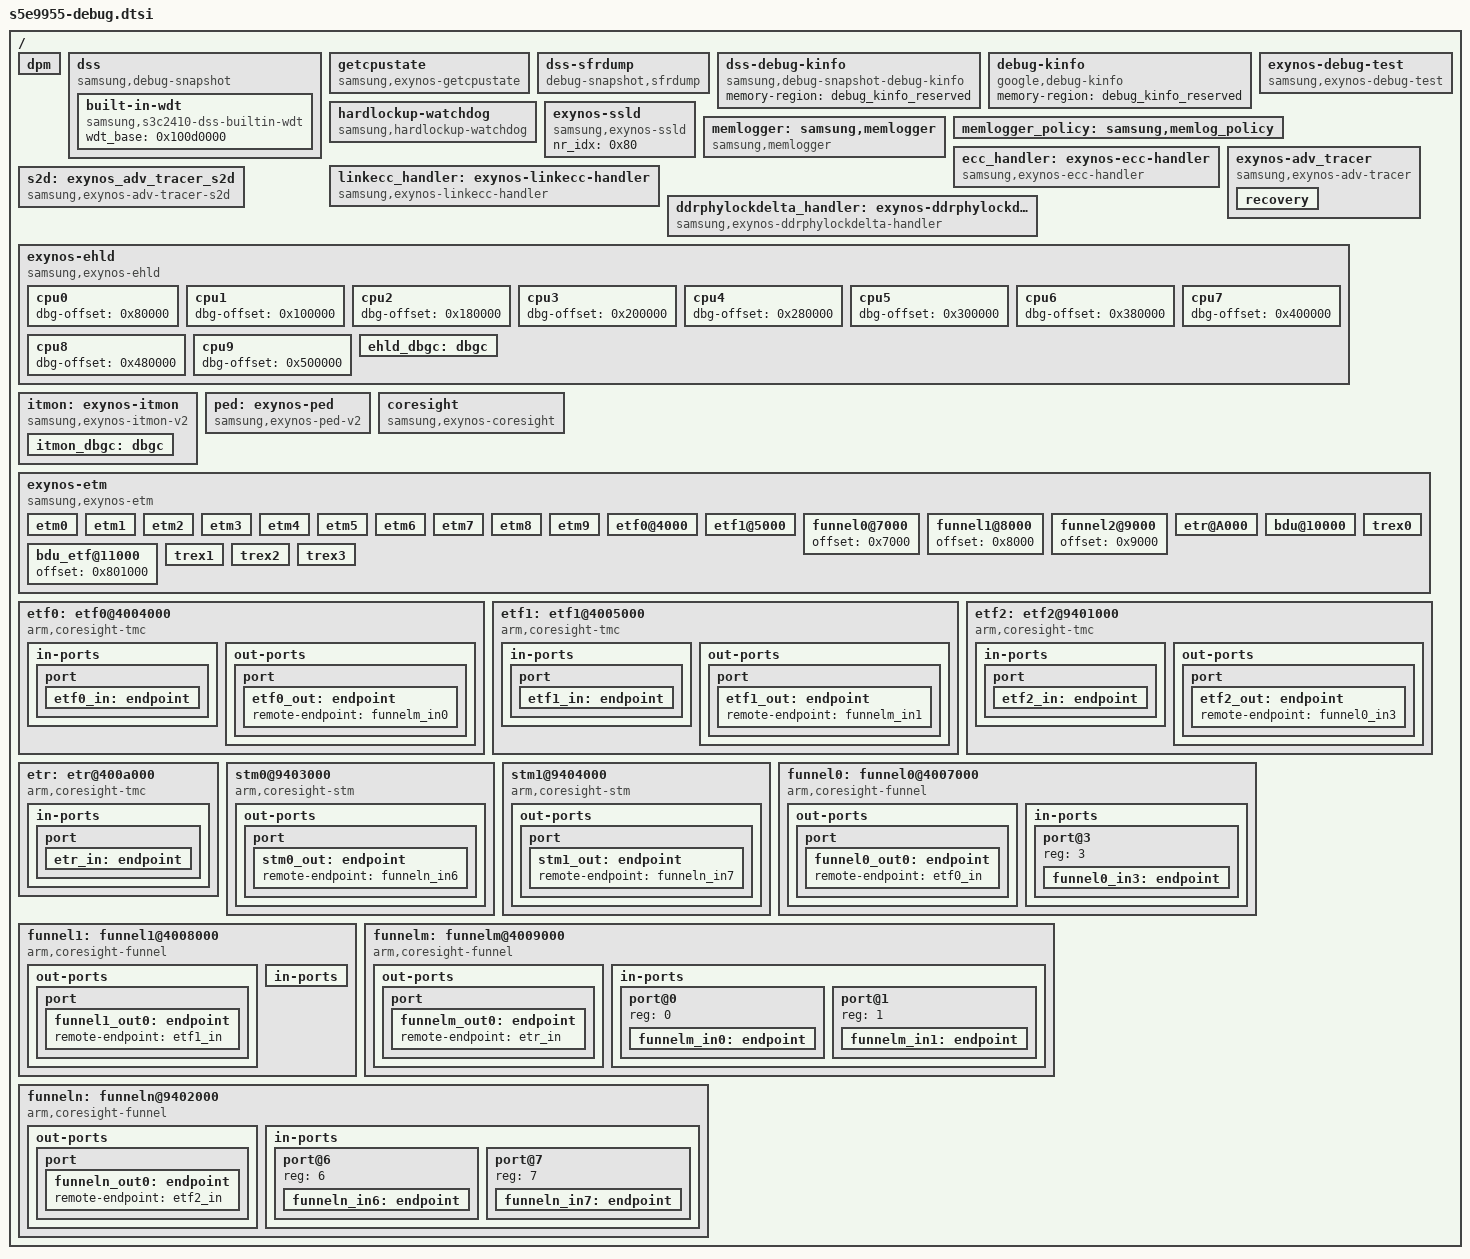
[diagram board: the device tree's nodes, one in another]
// SPDX-License-Identifier: GPL-2.0-only

#include <dt-bindings/interrupt-controller/s5e9955.h>
#include <dt-bindings/input/linux-event-codes.h>

/ {
	dpm: dpm {
	};

	dss: dss {
		compatible = "samsung,debug-snapshot";
		reg = <0 0x16915300 0xe00>;
		enable_cpuidle_dbg;
		panic_to_wdt = <0>;
		last_kmsg = <1>;
		hold-key = <KEY_VOLUMEDOWN>;
		trigger-key = <KEY_POWER>;
		scratch-disable = <0>;
		scratch-offset = <0x190>; /* SYSIP_DAT0 */
		scratch-bit = <6>;
		console_kmsg = <0>;
		freq_names = "CPUCL0", "CPUCL1", "CPUCL2", "CPUCL3", "DSU",
				"G3D", "MIF", "INT", "NPU", "AUD", "INTCAM",
				"CAM", "DISP", "CSIS", "ISP", "MFC", "MFD",
				"ICPU", "DSP", "DNC", "HSI0", "UFD", "UNPU";
		memory-region = <&header>, <&log_kernel>, <&log_s2d>,
				<&log_first>, <&log_arrdumprst>, <&log_platform>,
				<&log_kevents>, <&log_backtrace>, <&log_kevents_small>,
				<&wdtmsg>;
		built-in-wdt {
			compatible = "samsung,s3c2410-dss-builtin-wdt";
			wdt_base = <0x100d0000>;
		};
	};

	getcpustate {
		compatible = "samsung,exynos-getcpustate";
		reg = <0x0 0x2fc70000 0x2000>;
		reg-names = "dsu_base";
		control_by_dsu;
		core_ppuhwstat_offset = <0x1538>, <0x1538>, <0x1540>, <0x1540>,
					<0x1544>, <0x1544>, <0x1548>, <0x1548>,
					<0x154c>, <0x154c>;
		core_ppuhwstat_lsb = <0>, <16>, <0>, <16>,
				     <0>, <16>, <0>, <16>,
				     <0>, <16>;
	};

	dss-sfrdump {
		compatible = "debug-snapshot,sfrdump";
		/* -----------<< Example >>-------------------
		dump-info {
			#address-cells = <1>;
			#size-cells = <1>;

			gic-setenable {
				reg = <0x11f01100 0x100>;
			};
			gic-setpend {
				reg = <0x11f01200 0x100>;
			};
			gic-setactive {
				reg = <0x11f01300 0x100>;
			};
		};
		*/
	};

	dss-debug-kinfo {
		compatible = "samsung,debug-snapshot-debug-kinfo";
		memory-region = <&debug_kinfo_reserved>;
	};

	debug-kinfo {
		compatible = "google,debug-kinfo";
		memory-region = <&debug_kinfo_reserved>;
	};

	hardlockup-watchdog {
		compatible = "samsung,hardlockup-watchdog";
	};

	exynos-debug-test {
		compatible = "samsung,exynos-debug-test";
		ps_hold_control_offset = <0x3F90>;
		scratch-offset = <0x0190>; /* SYSIP_DAT0 */
		dram-init-bit = <0x4>;
		nr_cpu = <0x10>;
		nr_little_cpu = <0x2>;
		nr_mid_cpu = <0x5>;
		nr_mid_hf_cpu = <0x2>;
		nr_big_cpu = <0x1>;
		little_cpu_start = <0x0>;
		mid_cpu_start = <0x2>;
		mid_hf_cpu_start = <0x7>;
		big_cpu_start = <0x9>;
	};

	exynos-ssld {
		compatible = "samsung,exynos-ssld";
		nr_idx = <0x80>;
	};

	memlogger: samsung,memlogger {
		compatible = "samsung,memlogger";
		memory-region = <&memlog_mem>;
		samsung,bl-node = <&memlog_bl_base>;
	};

	memlogger_policy: samsung,memlog_policy {
		samsung,log-level = <4>;
		samsung,file-default-status = <1>;
		samsung,mem-constraint = <0>;
		samsung,mem-to-file-allow = <1>;
	};

	ecc_handler: exynos-ecc-handler {
		compatible = "samsung,exynos-ecc-handler";
		interrupts = <GIC_SPI INTREQ__CPUCL0_CLUSTERERRIRQ IRQ_TYPE_LEVEL_HIGH>,
			<GIC_SPI INTREQ__CPUCL0_COMPLEXERRIRQ_0 IRQ_TYPE_LEVEL_HIGH>,
			<GIC_SPI INTREQ__CPUCL0_COREERRIRQ_0 IRQ_TYPE_LEVEL_HIGH>,
			<GIC_SPI INTREQ__CPUCL0_COREERRIRQ_1 IRQ_TYPE_LEVEL_HIGH>,
			<GIC_SPI INTREQ__CPUCL0_COREERRIRQ_2 IRQ_TYPE_LEVEL_HIGH>,
			<GIC_SPI INTREQ__CPUCL0_COREERRIRQ_3 IRQ_TYPE_LEVEL_HIGH>,
			<GIC_SPI INTREQ__CPUCL0_COREERRIRQ_4 IRQ_TYPE_LEVEL_HIGH>,
			<GIC_SPI INTREQ__CPUCL0_COREERRIRQ_5 IRQ_TYPE_LEVEL_HIGH>,
			<GIC_SPI INTREQ__CPUCL0_COREERRIRQ_6 IRQ_TYPE_LEVEL_HIGH>,
			<GIC_SPI INTREQ__CPUCL0_COREERRIRQ_7 IRQ_TYPE_LEVEL_HIGH>,
			<GIC_SPI INTREQ__CPUCL0_COREERRIRQ_8 IRQ_TYPE_LEVEL_HIGH>,
			<GIC_SPI INTREQ__CPUCL0_COREERRIRQ_9 IRQ_TYPE_LEVEL_HIGH>,
			<GIC_SPI INTREQ__CPUCL0_CLUSTERFAULTIRQ IRQ_TYPE_LEVEL_HIGH>,
			<GIC_SPI INTREQ__CPUCL0_COMPLEXFAULTIRQ_0 IRQ_TYPE_LEVEL_HIGH>,
			<GIC_SPI INTREQ__CPUCL0_COREFAULTIRQ_0 IRQ_TYPE_LEVEL_HIGH>,
			<GIC_SPI INTREQ__CPUCL0_COREFAULTIRQ_1 IRQ_TYPE_LEVEL_HIGH>,
			<GIC_SPI INTREQ__CPUCL0_COREFAULTIRQ_2 IRQ_TYPE_LEVEL_HIGH>,
			<GIC_SPI INTREQ__CPUCL0_COREFAULTIRQ_3 IRQ_TYPE_LEVEL_HIGH>,
			<GIC_SPI INTREQ__CPUCL0_COREFAULTIRQ_4 IRQ_TYPE_LEVEL_HIGH>,
			<GIC_SPI INTREQ__CPUCL0_COREFAULTIRQ_5 IRQ_TYPE_LEVEL_HIGH>,
			<GIC_SPI INTREQ__CPUCL0_COREFAULTIRQ_6 IRQ_TYPE_LEVEL_HIGH>,
			<GIC_SPI INTREQ__CPUCL0_COREFAULTIRQ_7 IRQ_TYPE_LEVEL_HIGH>,
			<GIC_SPI INTREQ__CPUCL0_COREFAULTIRQ_8 IRQ_TYPE_LEVEL_HIGH>,
			<GIC_SPI INTREQ__CPUCL0_COREFAULTIRQ_9 IRQ_TYPE_LEVEL_HIGH>,
			<GIC_SPI INTREQ__CPUCL0_CLUSTERCRITIRQ IRQ_TYPE_LEVEL_HIGH>;
		interrupt-names = "Uncorrectable errors on the L3 data, tag or snoop filter RAMs",
			"Core0-1 Complex, Uncorrectable errors on the L2 data or tag RAMs",
			"Core0, Uncorrectable errors on the L1 data or tag RAMs",
			"Core1, Uncorrectable errors on the L1 data or tag RAMs",
			"Core2, Uncorrectable errors on the L1 data, tag or L2 data, tag RAMs",
			"Core3, Uncorrectable errors on the L1 data, tag or L2 data, tag RAMs",
			"Core4, Uncorrectable errors on the L1 data, tag or L2 data, tag RAMs",
			"Core5, Uncorrectable errors on the L1 data, tag or L2 data, tag RAMs",
			"Core6, Uncorrectable errors on the L1 data, tag or L2 data, tag RAMs",
			"Core7, Uncorrectable errors on the L1 data, tag or L2 data, tag RAMs",
			"Core8, Uncorrectable errors on the L1 data, tag or L2 data, tag RAMs",
			"Core9, Uncorrectable errors on the L1 data, tag or L2 data, tag RAMs",
			"FAULTIRQ(Single errors or Deffered errors) on the L3 data, tag or snoop filter RAMs",
			"Core0-1 Complex, FAULTIRQ(Single bit flip 100 times) on the L2 data or tag RAMs",
			"Core0, FAULTIRQ(Single bit flip 100 times) on the L1 data or tag RAMs",
			"Core1, FAULTIRQ(Single bit flip 100 times) on the L1 data or tag RAMs",
			"Core2, FAULTIRQ(Single bit flip 100 times) on the L1 data, tag or L2 data, tag RAMs",
			"Core3, FAULTIRQ(Single bit flip 100 times) on the L1 data, tag or L2 data, tag RAMs",
			"Core4, FAULTIRQ(Single bit flip 100 times) on the L1 data, tag or L2 data, tag RAMs",
			"Core5, FAULTIRQ(Single bit flip 100 times) on the L1 data, tag or L2 data, tag RAMs",
			"Core6, FAULTIRQ(Single bit flip 100 times) on the L1 data, tag or L2 data, tag RAMs",
			"Core7, FAULTIRQ(Single bit flip 100 times) on the L1 data, tag or L2 data, tag RAMs",
			"Core8, FAULTIRQ(Single bit flip 100 times) on the L1 data, tag or L2 data, tag RAMs",
			"Core9, FAULTIRQ(Single bit flip 100 times) on the L1 data, tag or L2 data, tag RAMs",
			"CRITIRQ(more than 2-bit bit-flip) on snoop filter";
		interrupt-affinity = <0x3ff>, <0x3>,
				<0x1>, <0x2>,
				<0x4>, <0x8>, <0x10>, <0x20>, <0x40>,
				<0x80>, <0x100>, <0x200>,
				<0x3ff>, <0x3>,
				<0x1>, <0x2>,
				<0x4>, <0x8>, <0x10>, <0x20>, <0x40>,
				<0x80>, <0x100>, <0x200>,
				<0x3ff>;
		policy = <0x0>, <0x0>,
				<0x0>, <0x0>,
				<0x0>, <0x0>, <0x0>, <0x0>, <0x0>,
				<0x0>, <0x0>, <0x0>,
				<0x1>, <0x0>,
				<0x0>, <0x0>,
				<0x0>, <0x0>, <0x0>, <0x0>, <0x0>,
				<0x0>, <0x0>, <0x0>,
				<0x0>;
	};
	
	linkecc_handler: exynos-linkecc-handler {
		compatible = "samsung,exynos-linkecc-handler";
		interrupts = <GIC_SPI INTREQ__DMC_ECC_CORERR_MIF0 IRQ_TYPE_LEVEL_HIGH>,
			<GIC_SPI INTREQ__DMC_ECC_UNCORERR_MIF0 IRQ_TYPE_LEVEL_HIGH>,
			<GIC_SPI INTREQ__DMC_ECC_CORERR_MIF1 IRQ_TYPE_LEVEL_HIGH>,
			<GIC_SPI INTREQ__DMC_ECC_UNCORERR_MIF1 IRQ_TYPE_LEVEL_HIGH>,
			<GIC_SPI INTREQ__DMC_ECC_CORERR_MIF2 IRQ_TYPE_LEVEL_HIGH>,
			<GIC_SPI INTREQ__DMC_ECC_UNCORERR_MIF2 IRQ_TYPE_LEVEL_HIGH>,
			<GIC_SPI INTREQ__DMC_ECC_CORERR_MIF3 IRQ_TYPE_LEVEL_HIGH>,
			<GIC_SPI INTREQ__DMC_ECC_UNCORERR_MIF3 IRQ_TYPE_LEVEL_HIGH>;
		interrupt-names = "Correctable error on CH0",
			"Uncorrectable errors on CH0",
			"Correctable error on CH1",
			"Uncorrectable errors on CH1",
			"Correctable error on CH2",
			"Uncorrectable errors on CH2",
			"Correctable error on CH3",
			"Uncorrectable errors on CH3";
		channel = <0x0>,<0x0>,<0x1>,<0x1>,<0x2>,<0x2>,<0x3>,<0x3>;
		clr_offs = <0x604>,<0x704>,<0x604>,<0x704>,<0x604>,<0x704>,<0x604>,<0x704>;
		base = <0x2D03F000>,<0x2D23F000>,<0x2D43F000>,<0x2D63F000>;
		debug_info = <0x02086400>;
	};	

	ddrphylockdelta_handler: exynos-ddrphylockdelta-handler {
		compatible = "samsung,exynos-ddrphylockdelta-handler";
		interrupts = <GIC_SPI INTREQ__DDRPHY_LOCKDELTA_MIF0 IRQ_TYPE_LEVEL_HIGH>,
			<GIC_SPI INTREQ__DDRPHY_LOCKDELTA_MIF1 IRQ_TYPE_LEVEL_HIGH>,
			<GIC_SPI INTREQ__DDRPHY_LOCKDELTA_MIF2 IRQ_TYPE_LEVEL_HIGH>,
			<GIC_SPI INTREQ__DDRPHY_LOCKDELTA_MIF3 IRQ_TYPE_LEVEL_HIGH>;
		interrupt-names = "DDRPHY Lockvalue Delta error on CH0",
			"DDRPHY Lockvalue Delta error on CH1",
			"DDRPHY Lockvalue Delta error on CH2",
			"DDRPHY Lockvalue Delta error on CH3";
		ch = <0x0>,<0x1>,<0x2>,<0x3>;
		base = <0x2D040000>,<0x2D240000>,<0x2D440000>,<0x2D640000>;
	};
	
	exynos-adv_tracer {
		compatible = "samsung,exynos-adv-tracer";
		reg = <0x0 0x13c10000 0x1000>;
		reg-names = "mailbox";
		interrupts = <GIC_SPI INTREQ__MAILBOX_DBGCORE2AP IRQ_TYPE_LEVEL_HIGH>;
		status = "ok";
		recovery {
			chip_name = "s5e9955";
			pmlink_out = <0x3e00>;
			pmlink_request = <0x25a0>;
			rst_seq = <0x0018>;
		};
	};

	s2d: exynos_adv_tracer_s2d {
		compatible = "samsung,exynos-adv-tracer-s2d";
		plugin-len = <3>;
		plugin-name = "S2D";
		pmu-burnin-ctrl = <0x3d48>;
		sel-scanmode-bit = <25>;
		dbgsel-sw-bit = <4>;
		pmu-rst-seq = <0x0018>;
		pmu-rst-seq-safe-mode-bit = <31>;
		status = "ok";
	};

	exynos-ehld {
		compatible = "samsung,exynos-ehld";
		status = "okay";
		cpu-end = <0x1>, <0x5>, <0x8>, <0x9>;
		reg = <0 0x2FCD0000 0x1000>,
			<0 0x2FCE0000 0x1000>,
			<0 0x2FCF0000 0x1000>,
			<0 0x2FD00000 0x1000>,
			<0 0x2FC90000 0x1000>,
			<0 0x2FCA0000 0x1000>,
			<0 0x2FCB0000 0x1000>,
			<0 0x2FCC0000 0x1000>;
		cs_base = <0x5000000>;
		version = <3>;
		cpu0 {
			dbg-offset = <0x80000>;
		};
		cpu1 {
			dbg-offset = <0x100000>;
		};
		cpu2 {
			dbg-offset = <0x180000>;
		};
		cpu3 {
			dbg-offset = <0x200000>;
		};
		cpu4 {
			dbg-offset = <0x280000>;
		};
		cpu5 {
			dbg-offset = <0x300000>;
		};
		cpu6 {
			dbg-offset = <0x380000>;
		};
		cpu7 {
			dbg-offset = <0x400000>;
		};
		cpu8 {
			dbg-offset = <0x480000>;
		};
		cpu9 {
			dbg-offset = <0x500000>;
		};

		ehld_dbgc: dbgc {
			/* IPC */
			plugin-len = <4>;
			plugin-name = "ELD";
			support = <1>;
			interval = <100>;
			threshold = <0x5000000>;
			judge = <1>;
			support-clear-data;
		};
	};

	itmon: exynos-itmon {
		compatible = "samsung,exynos-itmon-v2";
		memory-region = <&log_itmon>, <&log_itmon_history>;
		interrupts = <GIC_SPI INTREQ__TREX_DEBUG IRQ_TYPE_LEVEL_HIGH>;
		interrupt-affinity = <0x3ff>;
		support-irq-oring;
		big-bus-supporting;
		status = "ok";
		itmon_dbgc: dbgc {
			/* IPC */
			plugin-len = <3>;
			plugin-name = "ITM";
		};
	};

	ped: exynos-ped {
		compatible = "samsung,exynos-ped-v2";
		interrupts = <GIC_SPI INTREQ__PARITY_LH IRQ_TYPE_LEVEL_HIGH>;
		status = "okay";
	};

	coresight {
		compatible = "samsung,exynos-coresight";
		dbg_base = <0x5090000>, <0x5110000>, <0x5190000>, <0x5210000>,
			   <0x5290000>, <0x5310000>, <0x5390000>, <0x5410000>,
			   <0x5490000>, <0x5510000>;
		cti_base = <0x50f0000>, <0x5170000>, <0x51f0000>, <0x5270000>,
			   <0x52f0000>, <0x5370000>, <0x53f0000>, <0x5470000>,
			   <0x54f0000>, <0x5570000>;
		pmu_base = <0x50a0000>, <0x5120000>, <0x51a0000>, <0x5220000>,
			   <0x52a0000>, <0x5320000>, <0x53a0000>, <0x5420000>,
			   <0x54a0000>, <0x5520000>;
		gpr_base = <0x4001000>;
		dbgack-mask = <0x1ff00000>;
		halt = <0>;
		retention = <0>;
	};

	exynos-etm {
		compatible = "samsung,exynos-etm";
		cs_base = <0x4000000>;
		boot-start = <0>;
		funnel-num = <3>;
		funnel-port-num = <8>;
		etf-num = <2>;
		trex-num = <4>;
		/* funnel-port = <(funnel num) (port num)>; */
		etm0 {
			device_type = "etm";
			offset = <0x10b0000>;
			funnel-port = <0 0>;
		};
		etm1 {
			device_type = "etm";
			offset = <0x1130000>;
			funnel-port = <0 0>;
		};
		etm2 {
			device_type = "etm";
			offset = <0x11b0000>;
			funnel-port = <0 0>;
		};
		etm3 {
			device_type = "etm";
			offset = <0x1230000>;
			funnel-port = <0 0>;
		};
		etm4 {
			device_type = "etm";
			offset = <0x12b0000>;
			funnel-port = <0 0>;
		};
		etm5 {
			device_type = "etm";
			offset = <0x1330000>;
			funnel-port = <0 0>;
		};
		etm6 {
			device_type = "etm";
			offset = <0x13b0000>;
			funnel-port = <0 0>;
		};
		etm7 {
			device_type = "etm";
			offset = <0x1430000>;
			funnel-port = <0 0>;
		};
		etm8 {
			device_type = "etm";
			offset = <0x14b0000>;
			funnel-port = <0 0>;
		};
		etm9 {
			device_type = "etm";
			offset = <0x1530000>;
			funnel-port = <0 0>;
		};
		etf0@4000 {
			device_type = "etf";
			offset = <0x4000>;
			funnel-port = <2 0>;
		};
		etf1@5000 {
			device_type = "etf";
			offset = <0x5000>;
			funnel-port = <2 1>;
		};
		funnel0@7000 {
			device_type = "funnel";
			offset = <0x7000>;
		};
		funnel1@8000 {
			device_type = "funnel";
			offset = <0x8000>;
		};
		funnel2@9000 {
			device_type = "funnel";
			offset = <0x9000>;
		};
		etr@A000 {
			device_type = "etr";
			sfr_base = <0x400D000 0x100>;
			qch-offset = <0x2c>;
			offset = <0xA000>;
			buf-size = <0x100000>;
		};
		bdu@10000 {
			device_type = "bdu";
			offset = <0x800000>;
			funnel-port = <0 1>;
		};
		bdu_etf@11000 {
			device_type = "bdu_etf";
			offset = <0x801000>;
		};
		trex0 {
			device_type = "trex";
			mux_ctrl = <0x66>;
			dbg_trace_addr = <0x1ea83010>;
			dbg_trace_val = <5>;
		};
		trex1 {
			device_type = "trex";
			mux_ctrl = <0x77>;
			dbg_trace_addr = <0x1f603010>;
			dbg_trace_val = <26>;
		};
		trex2 {
			device_type = "trex";
			mux_ctrl = <0x88>;
			dbg_trace_addr = <0x204e3010>;
			dbg_trace_val = <8>;
		};
		trex3 {
			device_type = "trex";
			mux_ctrl = <0x55>;
			dbg_trace_addr = <0x1e503010>;
			dbg_trace_val = <8>;
		};
	};

	etf0: etf0@4004000 {
		compatible = "arm,coresight-tmc", "arm,primecell";
		arm,primecell-periphid = <0x001bb961>;
		reg = <0 0x4004000 0x1000>;
		clocks = <&clock MOUT_CLKCMU_CPUCL0_DBG_NOC_USER>;
		clock-names = "apb_pclk";
		in-ports {
			port {
				etf0_in: endpoint {
					slave-mode;
					remote-endpoint = <&funnel0_out0>;
				};
			};
		};

		out-ports {
			port {
				etf0_out: endpoint {
					remote-endpoint = <&funnelm_in0>;
				};
			};
		};
	};

	etf1: etf1@4005000 {
		compatible = "arm,coresight-tmc", "arm,primecell";
		arm,primecell-periphid = <0x001bb961>;
		reg = <0 0x4005000 0x1000>;
		clocks = <&clock MOUT_CLKCMU_CPUCL0_DBG_NOC_USER>;
		clock-names = "apb_pclk";
		in-ports {
			port {
				etf1_in: endpoint {
					slave-mode;
					remote-endpoint = <&funnel1_out0>;
				};
			};
		};

		out-ports {
			port {
				etf1_out: endpoint {
					remote-endpoint = <&funnelm_in1>;
				};
			};
		};
	};

	etf2: etf2@9401000 {
		compatible = "arm,coresight-tmc", "arm,primecell";
		arm,primecell-periphid = <0x001bb961>;
		reg = <0 0x9401000 0x1000>;
		clocks = <&clock UMUX_CLKCMU_DNC_NOC>;
		clock-names = "apb_pclk";
		power-domains = <&pd_dnc>;
		in-ports {
			port {
				etf2_in: endpoint {
					slave-mode;
					remote-endpoint = <&funneln_out0>;
				};
			};
		};

		out-ports {
			port {
				etf2_out: endpoint {
					remote-endpoint = <&funnel0_in3>;
				};
			};
		};
	};

	/* ETR sink */
	etr: etr@400a000 {
		compatible = "arm,coresight-tmc", "arm,primecell";
		arm,primecell-periphid = <0x001bb961>;
		reg = <0 0x400a000 0x1000>;
		clocks = <&clock MOUT_CLKCMU_CPUCL0_DBG_NOC_USER>;
		clock-names = "apb_pclk";
		samsung,cs-sfr = <0x400a000 0x100>;
		samsung,q-offset = <0x2c>;
		in-ports {
			port {
				etr_in: endpoint {
					slave-mode;
					remote-endpoint = <&funnelm_out0>;
				};
			};
		};
	};

	/* STM */
	stm0@9403000 {
		compatible = "arm,coresight-stm", "arm,primecell";
		arm,primecell-periphid = <0x0bb963>;
		reg = <0 0x9403000 0x1000>, <0 0x6000000 0x1000000>;
		reg-names = "stm-base", "stm-stimulus-base";
		clocks = <&clock UMUX_CLKCMU_DNC_NOC>;
		clock-names = "apb_pclk";
		power-domains = <&pd_dnc>;
		out-ports {
			port {
				stm0_out: endpoint {
					remote-endpoint = <&funneln_in6>;
				};
			};
		};
	};

	stm1@9404000 {
		compatible = "arm,coresight-stm", "arm,primecell";
		arm,primecell-periphid = <0x0bb963>;
		reg = <0 0x9404000 0x1000>, <0 0x7000000 0x1000000>;
		reg-names = "stm-base", "stm-stimulus-base";
		clocks = <&clock UMUX_CLKCMU_DNC_NOC>;
		clock-names = "apb_pclk";
		power-domains = <&pd_dnc>;
		out-ports {
			port {
				stm1_out: endpoint {
					remote-endpoint = <&funneln_in7>;
				};
			};
		};
	};


	funnel0: funnel0@4007000 {
		compatible = "arm,coresight-funnel", "arm,primecell";
		arm,primecell-periphid = <0x001bb908>;
		reg = <0 0x4007000 0x1000>;
		clocks = <&clock MOUT_CLKCMU_CPUCL0_DBG_NOC_USER>;
		clock-names = "apb_pclk";
		out-ports {
			port {
				funnel0_out0: endpoint {
					remote-endpoint = <&etf0_in>;
				};
			};
		};

		in-ports {
			#address-cells = <1>;
			#size-cells = <0>;

			port@3 {
				reg = <3>;
				funnel0_in3: endpoint {
					slave-mode;
					remote-endpoint = <&etf2_out>;
				};
			};
		};
	};

	funnel1: funnel1@4008000 {
		compatible = "arm,coresight-funnel", "arm,primecell";
		arm,primecell-periphid = <0x001bb908>;
		reg = <0 0x4008000 0x1000>;
		clocks = <&clock MOUT_CLKCMU_CPUCL0_DBG_NOC_USER>;
		clock-names = "apb_pclk";
		out-ports {
			port {
				funnel1_out0: endpoint {
					remote-endpoint = <&etf1_in>;
				};
			};
		};

		in-ports {
			#address-cells = <1>;
			#size-cells = <0>;
		};
	};

	funnelm: funnelm@4009000 {
		compatible = "arm,coresight-funnel", "arm,primecell";
		reg = <0 0x4009000 0x1000>;
		clocks = <&clock MOUT_CLKCMU_CPUCL0_DBG_NOC_USER>;
		clock-names = "apb_pclk";
		arm,primecell-periphid = <0x001bb908>;
		out-ports {
			port {
				funnelm_out0: endpoint {
					remote-endpoint = <&etr_in>;
				};
			};
		};

		in-ports {
			#address-cells = <1>;
			#size-cells = <0>;
			port@0 {
				reg = <0>;
				funnelm_in0: endpoint {
					slave-mode;
					remote-endpoint = <&etf0_out>;
				};
			};

			port@1 {
				reg = <1>;
				funnelm_in1: endpoint {
					slave-mode;
					remote-endpoint = <&etf1_out>;
				};
			};
		};
	};

	funneln: funneln@9402000 {
		compatible = "arm,coresight-funnel", "arm,primecell";
		arm,primecell-periphid = <0x001bb908>;
		reg = <0 0x9402000 0x1000>;
		clocks = <&clock UMUX_CLKCMU_DNC_NOC>;
		clock-names = "apb_pclk";
		power-domains = <&pd_dnc>;
		out-ports {
			port {
				funneln_out0: endpoint {
					remote-endpoint = <&etf2_in>;
				};
			};
		};

		in-ports {
			#address-cells = <1>;
			#size-cells = <0>;
			port@6 {
				reg = <6>;
				funneln_in6: endpoint {
					slave-mode;
					remote-endpoint = <&stm0_out>;
				};
			};

			port@7 {
				reg = <7>;
				funneln_in7: endpoint {
					slave-mode;
					remote-endpoint = <&stm1_out>;
				};
			};
		};
	};

};
